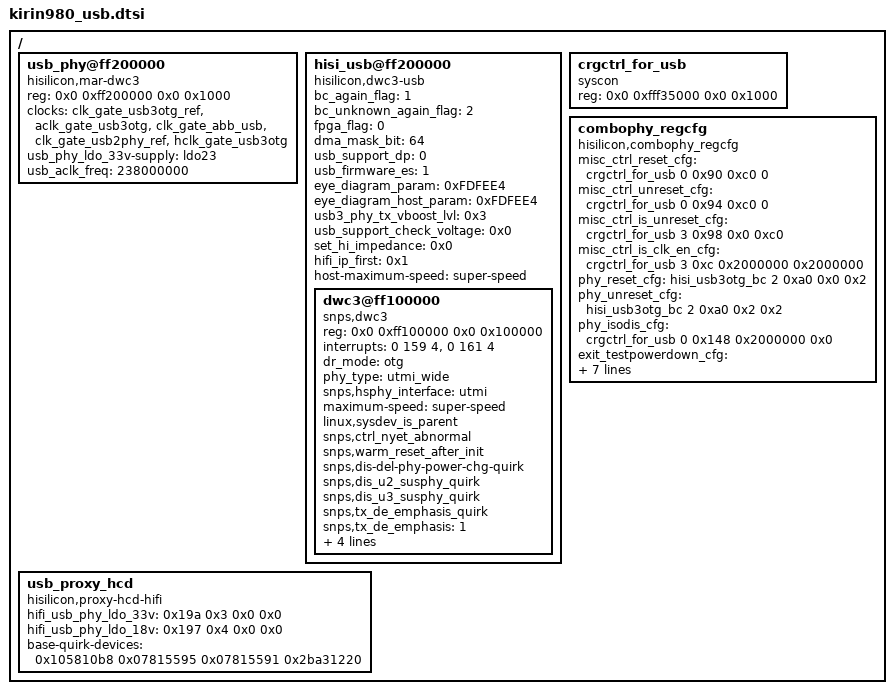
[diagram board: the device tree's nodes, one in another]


  /{
		usb_phy@ff200000 {
			compatible = "hisilicon,mar-dwc3";
			reg = <0x0 0xff200000 0x0 0x1000>;

			clocks = <&clk_gate_usb3otg_ref &aclk_gate_usb3otg &clk_gate_abb_usb &clk_gate_usb2phy_ref &hclk_gate_usb3otg>;
			clock-names = "clk_usb3phy_ref", "aclk_usb3otg", "clk_usb3_tcxo_en", "clk_usb2phy_ref", "hclk_usb3otg";

			/* usb 3.3v ldo */
			usb_phy_ldo_33v-supply = <&ldo23>;

			usb_aclk_freq = <238000000>;
		};

		hisi_usb@ff200000 {
			compatible = "hisilicon,dwc3-usb";
			ranges;
			bc_again_flag = <1>;
			bc_unknown_again_flag = <2>;
			fpga_flag = <0>;
			dma_mask_bit = <64>;

			/* just cs-udp open */
			usb_support_dp = <0>;

			/* just es open */
			usb_firmware_es = <1>;

			eye_diagram_param = <0xFDFEE4>;
			eye_diagram_host_param = <0xFDFEE4>;
			usb3_phy_tx_vboost_lvl = <0x3>;
			usb_support_check_voltage = <0x0>;
			set_hi_impedance = <0x0>;
			hifi_ip_first = <0x1>;

			/* udp-overlay super-speed-plus */
			host-maximum-speed = "super-speed";

			dwc3@ff100000 {
				compatible = "snps,dwc3";
				reg = <0x0 0xff100000 0x0 0x100000>;
				interrupts = <0 159 4>, <0 161 4>;
				interrupt-names = "irq", "otg_irq";
				dr_mode = "otg";
				phy_type = "utmi_wide";
				snps,hsphy_interface = "utmi";
				maximum-speed = "super-speed";
				linux,sysdev_is_parent;
				snps,ctrl_nyet_abnormal;
				snps,warm_reset_after_init;
				snps,dis-del-phy-power-chg-quirk;
				snps,dis_u2_susphy_quirk;
				snps,dis_u3_susphy_quirk;
				snps,tx_de_emphasis_quirk;
				snps,tx_de_emphasis = <1>;
				snps,dis-split-quirk;
				snps,gctl-reset-quirk;
				snps,xhci-delay-ctrl-data-stage;
				extcon = <&hisi_usb>;
			};
		};

		crgctrl_for_usb: crgctrl_for_usb {
			compatible = "syscon";
			reg = <0x0 0xfff35000 0x0 0x1000>;
		};

		combophy_regcfg {
			compatible = "hisilicon,combophy_regcfg";
			/* <syscon, cfg_type, offset, value, mask>*/
			/* cfg_type: 0-WRITE_ONLY, 1-BIT_MASK, 2-READ_WRITE, 3-TEST_READ */
			misc_ctrl_reset_cfg = <&crgctrl_for_usb 0 0x90 0xc0 0>;
			misc_ctrl_unreset_cfg = <&crgctrl_for_usb 0 0x94 0xc0 0>;
			misc_ctrl_is_unreset_cfg = <&crgctrl_for_usb 3 0x98 0x0 0xc0>;
			misc_ctrl_is_clk_en_cfg = <&crgctrl_for_usb 3 0xc 0x2000000 0x2000000>;
			phy_reset_cfg = <&hisi_usb3otg_bc 2 0xa0 0x0 0x2>;
			phy_unreset_cfg = <&hisi_usb3otg_bc 2 0xa0 0x2 0x2>;
			phy_isodis_cfg = <&crgctrl_for_usb 0 0x148 0x2000000 0x0>;
			exit_testpowerdown_cfg = <&hisi_usb3otg_bc 2 0x50 0x0 0x800000>;
			power_stable_cfg = <&hisi_usb3otg_bc 2 0x54 0xa02 0xa02>;
			is_controller_ref_clk_en_cfg = <&crgctrl_for_usb 3 0x4c 0x1 0x1>;
			is_controller_bus_clk_en_cfg = <&crgctrl_for_usb 3 0x4c 0x2 0x2>;
		};

		usb_proxy_hcd {
			compatible = "hisilicon,proxy-hcd-hifi";
			hifi_usb_phy_ldo_33v = <0x19a 0x3 0x0 0x0>;
			hifi_usb_phy_ldo_18v = <0x197 0x4 0x0 0x0>;
			base-quirk-devices = <
				/* format:0xVIDPID */
				/* Western Digital - Elements 10B8 */
				0x105810b8
				/* SanDisk - Ultra USB 3.0 */
				0x07815595
				0x07815591
				/* CBM - Flash disk */
				0x2ba31220
			>;
		};
  };
